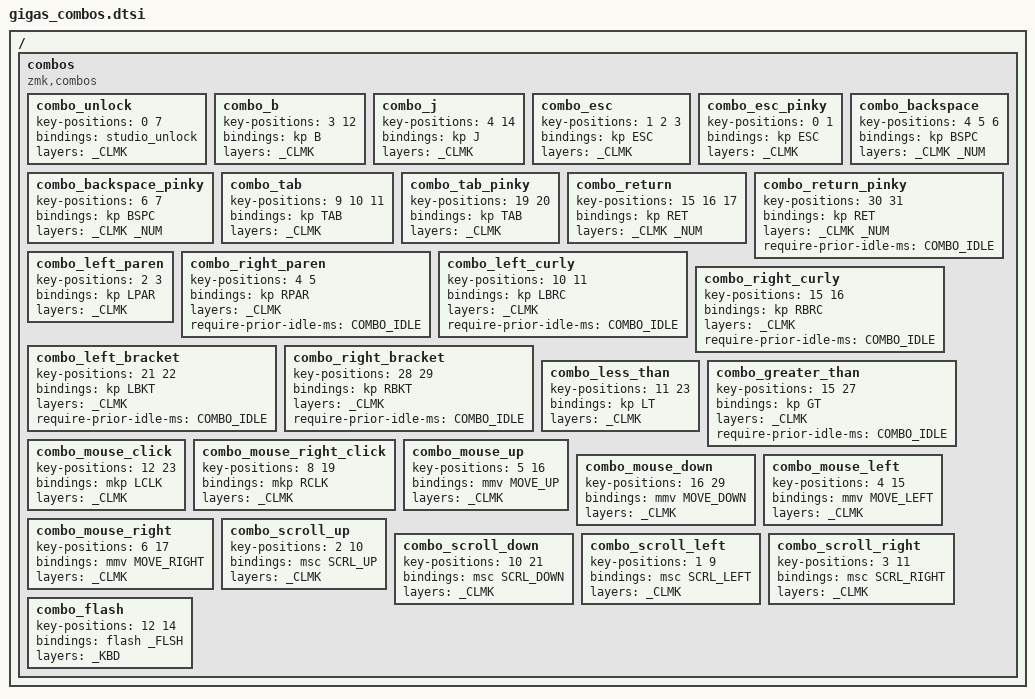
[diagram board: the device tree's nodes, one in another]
// Key positions for combos
// ┏━━━━┳━━━━┳━━━━┳━━━━┓                          ┏━━━━┳━━━━┳━━━━┳━━━━┓
// ┃ 0  ┃ 1  ┃ 2  ┃ 3  ┃                          ┃ 4  ┃ 5  ┃ 6  ┃ 7  ┃
// ┣━━━━╋━━━━╋━━━━╋━━━━╋━━━━┓     ┏━━━━┓     ┏━━━━╋━━━━╋━━━━╋━━━━╋━━━━┫
// ┃ 8  ┃ 9  ┃ 10 ┃<11>┃ 12 ┃     ┃ 13 ┃     ┃ 14 ┃<15>┃ 16 ┃ 17 ┃ 18 ┃
// ┣━━━━╋━━━━╋━━━━╋━━━━╋━━━━┫┏━━━━╋━━━━╋━━━━┓┣━━━━╋━━━━╋━━━━╋━━━━╋━━━━┫
// ┃ 19 ┃ 20 ┃ 21 ┃ 22 ┃ 23 ┃┃ 24 ┃[25]┃ 26 ┃┃ 27 ┃ 28 ┃ 29 ┃ 30 ┃ 31 ┃
// ┗━━━━┻━━━━┻━━━━┻━━━━╋━━━━╋┻━━━┳╋━━━━╋┳━━━┻╋━━━━╋━━━━┻━━━━┻━━━━┻━━━━┛
//                     ┃ 32 ┃<33>┃┃ 34 ┃┃<35>┃ 36 ┃
//                     ┗━━━━┻━━━━┛┗━━━━┛┗━━━━┻━━━━┛

#define COMBO_IDLE 250

/ {
    combos {
        compatible = "zmk,combos";

        combo_unlock {
            key-positions = <0 7>;
            bindings = <&studio_unlock>;
            layers = <_CLMK>;
        };

        combo_b {
            key-positions = <3 12>;
            bindings = <&kp B>;
            layers = <_CLMK>;
        };

        combo_j {
            key-positions = <4 14>;
            bindings = <&kp J>;
            layers = <_CLMK>;
        };

        combo_esc {
            key-positions = <1 2 3>;
            bindings = <&kp ESC>;
            layers = <_CLMK>;
        };

        combo_esc_pinky {
            key-positions = <0 1>;
            bindings = <&kp ESC>;
            layers = <_CLMK>;
        };

        combo_backspace {
            key-positions = <4 5 6>;
            bindings = <&kp BSPC>;
            layers = <_CLMK _NUM>;
        };

        combo_backspace_pinky {
            key-positions = <6 7>;
            bindings = <&kp BSPC>;
            layers = <_CLMK _NUM>;
        };

        combo_tab {
            key-positions = <9 10 11>;
            bindings = <&kp TAB>;
            layers = <_CLMK>;
        };

        combo_tab_pinky {
            key-positions = <19 20>;
            bindings = <&kp TAB>;
            layers = <_CLMK>;
        };

        combo_return {
            key-positions = <15 16 17>;
            bindings = <&kp RET>;
            layers = <_CLMK _NUM>;
        };

        combo_return_pinky {
            key-positions = <30 31>;
            bindings = <&kp RET>;
            layers = <_CLMK _NUM>;
            require-prior-idle-ms = <COMBO_IDLE>;
        };

        combo_left_paren {
            key-positions = <2 3>;
            bindings = <&kp LPAR>;
            layers = <_CLMK>;
        };

        combo_right_paren {
            key-positions = <4 5>;
            bindings = <&kp RPAR>;
            layers = <_CLMK>;
            require-prior-idle-ms = <COMBO_IDLE>;
        };

        combo_left_curly {
            key-positions = <10 11>;
            bindings = <&kp LBRC>;
            layers = <_CLMK>;
            require-prior-idle-ms = <COMBO_IDLE>;
        };

        combo_right_curly {
            key-positions = <15 16>;
            bindings = <&kp RBRC>;
            layers = <_CLMK>;
            require-prior-idle-ms = <COMBO_IDLE>;
        };

        combo_left_bracket {
            key-positions = <21 22>;
            bindings = <&kp LBKT>;
            layers = <_CLMK>;
            require-prior-idle-ms = <COMBO_IDLE>;
        };

        combo_right_bracket {
            key-positions = <28 29>;
            bindings = <&kp RBKT>;
            layers = <_CLMK>;
            require-prior-idle-ms = <COMBO_IDLE>;
        };

        combo_less_than {
            key-positions = <11 23>;
            bindings = <&kp LT>;
            layers = <_CLMK>;
        };

        combo_greater_than {
            key-positions = <15 27>;
            bindings = <&kp GT>;
            layers = <_CLMK>;
            require-prior-idle-ms = <COMBO_IDLE>;
        };

        combo_mouse_click {
            key-positions = <12 23>;
            bindings = <&mkp LCLK>;
            layers = <_CLMK>;
        };

        combo_mouse_right_click {
            key-positions = <8 19>;
            bindings = <&mkp RCLK>;
            layers = <_CLMK>;
        };

        combo_mouse_up {
            key-positions = <5 16>;
            bindings = <&mmv MOVE_UP>;
            layers = <_CLMK>;
        };

        combo_mouse_down {
            key-positions = <16 29>;
            bindings = <&mmv MOVE_DOWN>;
            layers = <_CLMK>;
        };

        combo_mouse_left {
            key-positions = <4 15>;
            bindings = <&mmv MOVE_LEFT>;
            layers = <_CLMK>;
        };

        combo_mouse_right {
            key-positions = <6 17>;
            bindings = <&mmv MOVE_RIGHT>;
            layers = <_CLMK>;
        };

        combo_scroll_up {
            key-positions = <2 10>;
            bindings = <&msc SCRL_UP>;
            layers = <_CLMK>;
        };

        combo_scroll_down {
            key-positions = <10 21>;
            bindings = <&msc SCRL_DOWN>;
            layers = <_CLMK>;
        };

        combo_scroll_left {
            key-positions = <1 9>;
            bindings = <&msc SCRL_LEFT>;
            layers = <_CLMK>;
        };

        combo_scroll_right {
            key-positions = <3 11>;
            bindings = <&msc SCRL_RIGHT>;
            layers = <_CLMK>;
        };

        // Combos are always executed on the central, so if we have a dongle
        // without an easily accessible reset button, we can use a combo to
        // put the central into bootloder mode
        combo_flash {
            key-positions = <12 14>;
            bindings = <&flash _FLSH>;
            layers = <_KBD>;
        };
    };
};

// vim: expandtab softtabstop=4 shiftwidth=4
